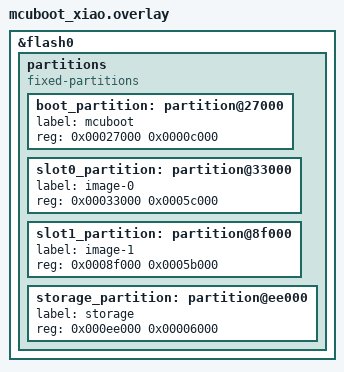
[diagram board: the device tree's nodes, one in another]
/* MCUboot for the XIAO OTA build: the partition labels it needs, the same layout as
 * pm_static/mcuboot_xiao_ble.yml (which the build uses for the actual placement).
 * MCUboot is built for nrf52840dk/nrf52840: its own partition table is replaced. */
&flash0 {
	/delete-node/ partitions;

	partitions {
		compatible = "fixed-partitions";
		#address-cells = <1>;
		#size-cells = <1>;

		boot_partition: partition@27000 {
			label = "mcuboot";
			reg = <0x00027000 0x0000c000>;
		};
		slot0_partition: partition@33000 {
			label = "image-0";
			reg = <0x00033000 0x0005c000>;
		};
		slot1_partition: partition@8f000 {
			label = "image-1";
			reg = <0x0008f000 0x0005b000>;
		};
		storage_partition: partition@ee000 {
			label = "storage";
			reg = <0x000ee000 0x00006000>;
		};
	};
};
